# COMPUTE_CLUSTER0_DRU_MMR_FW_GLB register map
Vendor: Texas Instruments
Peripheral module from a debugger description file (folder am65x).
Registers are 32-bit, read-only, reset values left out (the file's numbers can be read two ways) unless marked. A register's access mark holds for its fields unless they carry their own. Offsets are as the file gives them; lines under a group give offsets from that group; [hi:lo] are bit positions; {n}, {i} and the like mark numbered series; 'fields as' and 'values as' point back to an identical list; <NAME> marks a mode.

## COMPUTE_CLUSTER0_DRU_MMR_FW_GLB
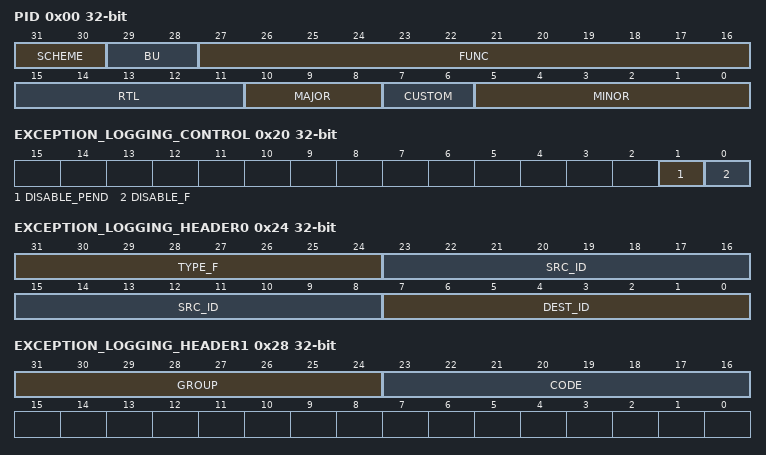
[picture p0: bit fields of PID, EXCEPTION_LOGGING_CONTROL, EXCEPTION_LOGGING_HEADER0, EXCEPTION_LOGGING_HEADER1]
0x00 PID — The Revision Register contains the major and minor revisions for the module.
  [31:30] SCHEME — PID register scheme
  [29:28] BU — Business Unit:10 = Processors
  [27:16] FUNC — Module ID
  [15:11] RTL — RTL revision.Will vary depending on release.
  [10:8] MAJOR — Major revision
  [7:6] CUSTOM
  [5:0] MINOR — Minor revision
0x04 DESTINATION_ID rw — The Destination ID Register defines the destination ID value for error messages.
  [7:0] DEST_ID — The destination ID.
0x20 EXCEPTION_LOGGING_CONTROL rw — The Exception Logging Control Register controls the exception logging.
  [1] DISABLE_PEND — Disables logging pending when set.
  [0] DISABLE_F — Disables logging when set.
0x24 EXCEPTION_LOGGING_HEADER0 — The Exception Logging Header 0 Register contains the first word of the header.
  [31:24] TYPE_F — Type.
  [23:8] SRC_ID — Source ID.
  [7:0] DEST_ID — Destination ID.
0x28 EXCEPTION_LOGGING_HEADER1 — The Exception Logging Header 1 Register contains the second word of the header.
  [31:24] GROUP, [23:16] CODE
0x2C EXCEPTION_LOGGING_DATA0 — The Exception Logging Data 0 Register contains the first word of the data.
  [31:0] ADDR_L — Address lower 32 bits.
0x30 EXCEPTION_LOGGING_DATA1 — The Exception Logging Data 1 Register contains the second word of the data.
  [15:0] ADDR_H — Address upper 16 bits.
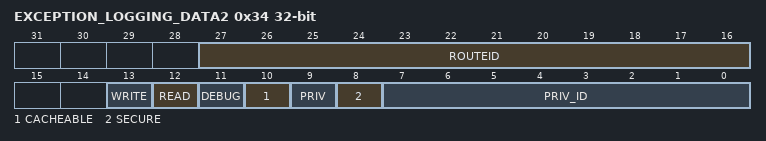
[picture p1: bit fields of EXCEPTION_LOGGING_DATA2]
0x34 EXCEPTION_LOGGING_DATA2 — The Exception Logging Data 2 Register contains the third word of the data.
  [27:16] ROUTEID, [13] WRITE, [12] READ, [11] DEBUG, [10] CACHEABLE, [9] PRIV, [8] SECURE, [7:0] PRIV_ID
0x38 EXCEPTION_LOGGING_DATA3 — The Exception Logging Data 3 Register contains the fourth word of the data.
  [9:0] BYTECNT — Byte count.
0x40 EXCEPTION_PEND_SET access not given — The Exception Logging Pending Set Register allows to set the pend signal.
  [0] PEND_SET — Write a 1 to set the exception pend signal. (access RW1S)
0x44 EXCEPTION_PEND_CLEAR access not given — The Exception Logging Pending Clear Register allows to clear the pend signal.
  [0] PEND_CLR — Write a 1 to clear the exception pend signal. (access RW1C)
